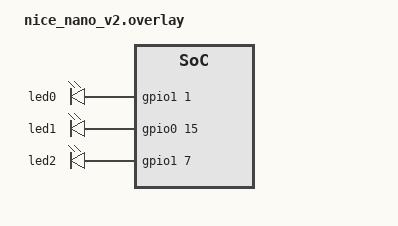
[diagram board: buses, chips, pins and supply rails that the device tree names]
/ {
    aliases {
        led-red = &led0; 
        led-blue = &led1;
        led-green = &led2;
    };

    leds {
        compatible = "gpio-leds";
        status = "okay";
        led0: led_0 {
            gpios = <&gpio1 1 (GPIO_ACTIVE_HIGH | GPIO_PULL_DOWN)>;  // red LED, connected to P1.01
        };
        led1: led_1 {
            gpios = <&gpio0 15 (GPIO_ACTIVE_HIGH)>;  // blue LED, connected to P0.15
        };
        led2: led_2 {
            gpios = <&gpio1 7 (GPIO_ACTIVE_HIGH | GPIO_PULL_DOWN)>;  // green LED, connected to P1.07
        };
  };
};
